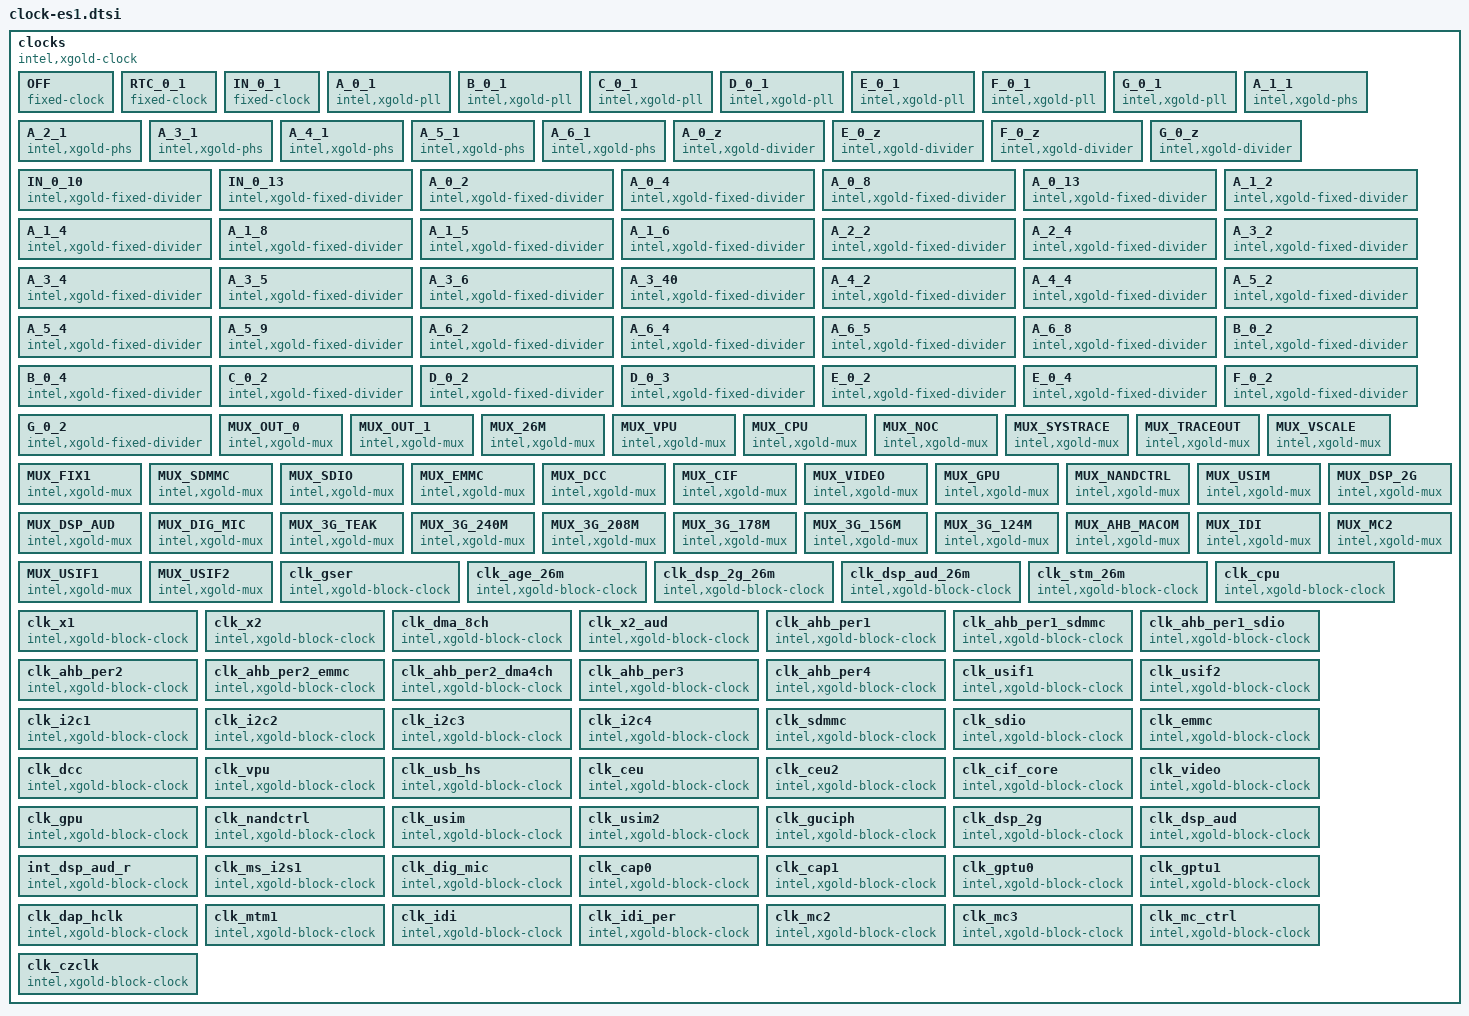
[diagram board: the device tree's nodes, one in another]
clocks {
	compatible = "intel,xgold-clock";
	intel,reg-phys = <&cgu>;
	intel,reg-defaults = <1364 0xFFFFFFFF 2636 0x0 2652 0x0 384 0x0 2640 0x0 2592 0x10008 2632 0x0 1360 0xFFFFFFFF 2644 0x30 2656 0x2495A 2660 0xE1FF0000 1368 0xFFFFFFFF>;
	intel,vreq-mapping = <1 2 3 7>;
	intel,cpu-vreq = <2652 7 3>;
	intel,global-vreq = <2652 10 3>;
	OFF:OFF {
		compatible = "fixed-clock";
		#clock-cells = <0>;
		clock-frequency= <0>;
		clock-output-names = "OFF";
	};
	RTC_0_1:RTC_0_1 {
		compatible = "fixed-clock";
		#clock-cells = <0>;
		clock-frequency= <32000>;
		clock-output-names = "RTC_0_1";
	};
	IN_0_1:IN_0_1 {
		compatible = "fixed-clock";
		#clock-cells = <0>;
		clock-frequency= <26000000>;
		clock-output-names = "IN_0_1";
	};
	A_0_1:A_0_1 {
		compatible = "intel,xgold-pll";
		#clock-cells = <0>;
		clock-frequency= <416000000>;
		clock-output-names = "A_0_1";
		clocks = <&IN_0_1>;
		clock-names = "ref";
		intel,pll-type = "analog";
		intel,pll-parameters = < 15 0 15 0 15 0 >;
		intel,mux-banks = < 3 >;
		intel,pll-mux = <292 8 1 296 8 1 300 8 1>;
		intel,pll-mult = <288 16 8>;
		intel,pll-up = <288 0 1>;
		intel,pll-div = <288 12 4>;
		intel,pll-status-lock = <356 16 1>;
		intel,pll-status-mux = <360 8 1>;
	};
	B_0_1:B_0_1 {
		compatible = "intel,xgold-pll";
		#clock-cells = <0>;
		clock-frequency= <1000000000>;
		clock-output-names = "B_0_1";
		clocks = <&IN_0_1>;
		clock-names = "ref";
		intel,flags-cpu;
		intel,pll-type = "digital";
		intel,pll-parameters = < 720896 1 983040 1 1950956 1 2455080 1 >;
		intel,pll-up-init = < 1 1 1 1 >;
		intel,frequency-banks = < 4 >;
		intel,mux-banks = < 4 >;
		intel,pll-mux = <304 1 1 996 1 1 1000 1 1 1004 1 1>;
		intel,pll-mult = <304 4 23 996 4 23 1000 4 23 1004 4 23>;
		intel,pll-up = <304 0 1 996 0 1 1000 0 1 1004 0 1>;
		intel,pll-status-lock = <356 17 1>;
		intel,pll-shpu = <304 3 1 996 3 1 1000 3 1 1004 3 1>;
		intel,pll-update = <348 17 1>;
	};
	C_0_1:C_0_1 {
		compatible = "intel,xgold-pll";
		#clock-cells = <0>;
		clock-frequency= <442000000>;
		clock-output-names = "C_0_1";
		clocks = <&IN_0_1>;
		clock-names = "ref";
		intel,pll-type = "analog";
		intel,pll-parameters = < 16 0 16 0 16 0 >;
		intel,pll-mux = <308 8 1>;
		intel,pll-mult = <308 16 8>;
		intel,pll-up = <308 0 1>;
		intel,pll-div = <308 12 4>;
		intel,pll-status-lock = <356 18 1>;
	};
	D_0_1:D_0_1 {
		compatible = "intel,xgold-pll";
		#clock-cells = <0>;
		clock-frequency= <312000000>;
		clock-output-names = "D_0_1";
		clocks = <&IN_0_1>;
		clock-names = "ref";
		intel,pll-type = "analog";
		intel,pll-parameters = < 11 0 11 0 11 0 >;
		intel,pll-up = <372 28 1>;
		intel,pll-status-lock = <356 19 1>;
	};
	E_0_1:E_0_1 {
		compatible = "intel,xgold-pll";
		#clock-cells = <0>;
		clock-frequency= <480000000>;
		clock-output-names = "E_0_1";
		clocks = <&IN_0_1>;
		clock-names = "ref";
		intel,pll-type = "digital";
		intel,pll-parameters = < 1144359 1 >;
		intel,pll-mux = <312 1 1>;
		intel,pll-mult = <312 4 23>;
		intel,pll-up = <312 0 1>;
		intel,pll-status-lock = <356 20 1>;
		intel,pll-update = <348 20 1>;
	};
	F_0_1:F_0_1 {
		compatible = "intel,xgold-pll";
		#clock-cells = <0>;
		clock-frequency= <800000000>;
		clock-output-names = "F_0_1";
		clocks = <&IN_0_1>;
		clock-names = "ref";
		intel,flags-noinit;
		intel,flags-ignore-unused;
		intel,pll-type = "digital";
		intel,pll-parameters = < 1114112 1 >;
		intel,pll-mux = <320 1 1>;
		intel,pll-mult = <320 4 23>;
		intel,pll-up = <320 0 1>;
		intel,pll-status-lock = <356 21 1>;
		intel,pll-shpu = <320 3 1>;
		intel,pll-update = <348 21 1>;
	};
	G_0_1:G_0_1 {
		compatible = "intel,xgold-pll";
		#clock-cells = <0>;
		clock-frequency= <400000000>;
		clock-output-names = "G_0_1";
		clocks = <&IN_0_1>;
		clock-names = "ref";
		intel,pll-type = "digital";
		intel,pll-parameters = < 993122 1 >;
		intel,pll-mux = <980 1 1>;
		intel,pll-mult = <980 4 23>;
		intel,pll-up = <980 0 1>;
		intel,pll-status-lock = <356 22 1>;
		intel,pll-update = <348 22 1>;
	};
	A_1_1:A_1_1 {
		compatible = "intel,xgold-phs";
		#clock-cells = <0>;
		clock-output-names = "A_1_1";
		clocks = <&A_0_1>;
		clock-names = "ref";
		intel,phs-parameters = < 2 1 >;
		intel,frequency-banks = < 3 >;
		intel,mux-banks = < 3 >;
		intel,phs-mux = <292 9 1 296 9 1 300 9 1>;
		intel,phs-Y = <324 3 4 328 3 4 332 3 4>;
		intel,phs-up = <292 1 1 296 1 1 300 1 1>;
		intel,phs-X = <324 0 3 328 0 3 332 0 3>;
		intel,phs-status-up = <360 1 1>;
		intel,phs-status-Y = <364 3 4>;
		intel,phs-status-X = <364 0 3>;
		intel,phs-status-mux = <360 9 1>;
		intel,phs-update = <348 0 1>;
	};
	A_2_1:A_2_1 {
		compatible = "intel,xgold-phs";
		#clock-cells = <0>;
		clock-output-names = "A_2_1";
		clocks = <&A_0_1>;
		clock-names = "ref";
		intel,phs-parameters = < 4 1 4 1 4 1 >;
		intel,frequency-banks = < 3 >;
		intel,mux-banks = < 3 >;
		intel,phs-mux = <292 10 1 296 10 1 300 10 1>;
		intel,phs-Y = <324 11 4 328 11 4 332 11 4>;
		intel,phs-up = <292 2 1 296 2 1 300 2 1>;
		intel,phs-X = <324 8 3 328 8 3 332 8 3>;
		intel,phs-status-up = <360 2 1>;
		intel,phs-status-Y = <364 11 4>;
		intel,phs-status-X = <364 8 3>;
		intel,phs-status-mux = <360 10 1>;
		intel,phs-update = <348 1 1>;
	};
	A_3_1:A_3_1 {
		compatible = "intel,xgold-phs";
		#clock-cells = <0>;
		clock-output-names = "A_3_1";
		clocks = <&A_0_1>;
		clock-names = "ref";
		intel,phs-parameters = < 1 2 1 2 1 2 >;
		intel,frequency-banks = < 3 >;
		intel,mux-banks = < 3 >;
		intel,phs-mux = <292 11 1 296 11 1 300 11 1>;
		intel,phs-Y = <324 19 4 328 19 4 332 19 4>;
		intel,phs-up = <292 3 1 296 3 1 300 3 1>;
		intel,phs-X = <324 16 3 328 16 3 332 16 3>;
		intel,phs-status-up = <360 3 1>;
		intel,phs-status-Y = <364 19 4>;
		intel,phs-status-X = <364 16 3>;
		intel,phs-status-mux = <360 11 1>;
		intel,phs-update = <348 2 1>;
	};
	A_4_1:A_4_1 {
		compatible = "intel,xgold-phs";
		#clock-cells = <0>;
		clock-output-names = "A_4_1";
		clocks = <&A_0_1>;
		clock-names = "ref";
		intel,phs-parameters = < 1 1 1 1 1 1 >;
		intel,frequency-banks = < 3 >;
		intel,mux-banks = < 3 >;
		intel,phs-mux = <292 12 1 296 12 1 300 12 1>;
		intel,phs-Y = <324 27 4 328 27 4 332 27 4>;
		intel,phs-up = <292 4 1 296 4 1 300 4 1>;
		intel,phs-X = <324 24 3 328 24 3 332 24 3>;
		intel,phs-status-up = <360 4 1>;
		intel,phs-status-Y = <364 27 4>;
		intel,phs-status-X = <364 24 3>;
		intel,phs-status-mux = <360 12 1>;
		intel,phs-update = <348 3 1>;
	};
	A_5_1:A_5_1 {
		compatible = "intel,xgold-phs";
		#clock-cells = <0>;
		clock-output-names = "A_5_1";
		clocks = <&A_0_1>;
		clock-names = "ref";
		intel,phs-parameters = < 3 1 3 1 3 1 >;
		intel,frequency-banks = < 3 >;
		intel,mux-banks = < 3 >;
		intel,phs-mux = <292 13 1 296 13 1 300 13 1>;
		intel,phs-Y = <336 3 4 340 3 4 344 3 4>;
		intel,phs-up = <292 5 1 296 5 1 300 5 1>;
		intel,phs-X = <336 8 3 340 8 3 344 8 3>;
		intel,phs-status-up = <360 5 1>;
		intel,phs-status-Y = <368 3 4>;
		intel,phs-status-X = <368 0 3>;
		intel,phs-status-mux = <360 13 1>;
		intel,phs-update = <348 5 1>;
	};
	A_6_1:A_6_1 {
		compatible = "intel,xgold-phs";
		#clock-cells = <0>;
		clock-output-names = "A_6_1";
		clocks = <&A_0_1>;
		clock-names = "ref";
		intel,phs-parameters = < 0 1 0 1 0 1 >;
		intel,frequency-banks = < 3 >;
		intel,mux-banks = < 3 >;
		intel,phs-mux = <292 14 1 296 14 1 300 14 1>;
		intel,phs-Y = <336 11 4 340 11 4 344 11 4>;
		intel,phs-up = <292 6 1 296 6 1 300 6 1>;
		intel,phs-X = <336 8 3 340 8 3 344 8 3>;
		intel,phs-status-up = <360 6 1>;
		intel,phs-status-Y = <368 11 4>;
		intel,phs-status-X = <368 8 3>;
		intel,phs-status-mux = <360 14 1>;
		intel,phs-update = <348 6 1>;
	};
	A_0_z:A_0_z {
		compatible = "intel,xgold-divider";
		#clock-cells = <0>;
		clock-output-names = "A_0_z";
		clocks = <&A_0_1>;
		clock-names = "ref";
		intel,divider-type = "Natural";
		intel,divider-div = <288 28 4>;
	};
	E_0_z:E_0_z {
		compatible = "intel,xgold-divider";
		#clock-cells = <0>;
		clock-output-names = "E_0_z";
		clocks = <&E_0_1>;
		clock-names = "ref";
		intel,divider-type = "Natural";
		intel,divider-div = <312 28 4>;
	};
	F_0_z:F_0_z {
		compatible = "intel,xgold-divider";
		#clock-cells = <0>;
		clock-output-names = "F_0_z";
		clocks = <&F_0_1>;
		clock-names = "ref";
		intel,divider-type = "Natural";
		intel,divider-div = <320 28 4>;
	};
	G_0_z:G_0_z {
		compatible = "intel,xgold-divider";
		#clock-cells = <0>;
		clock-output-names = "G_0_z";
		clocks = <&G_0_1>;
		clock-names = "ref";
		intel,divider-type = "Natural";
		intel,divider-div = <980 28 4>;
	};
	IN_0_10:IN_0_10 {
		compatible = "intel,xgold-fixed-divider";
		#clock-cells = <0>;
		clock-output-names = "IN_0_10";
		clocks = <&IN_0_1>;
		clock-names = "ref";
		intel,divider = < 10 >;
		intel,mult = < 1 >;
	};
	IN_0_13:IN_0_13 {
		compatible = "intel,xgold-fixed-divider";
		#clock-cells = <0>;
		clock-output-names = "IN_0_13";
		clocks = <&IN_0_1>;
		clock-names = "ref";
		intel,divider = < 13 >;
		intel,mult = < 1 >;
	};
	A_0_2:A_0_2 {
		compatible = "intel,xgold-fixed-divider";
		#clock-cells = <0>;
		clock-output-names = "A_0_2";
		clocks = <&A_0_1>;
		clock-names = "ref";
		intel,divider = < 2 >;
		intel,mult = < 1 >;
	};
	A_0_4:A_0_4 {
		compatible = "intel,xgold-fixed-divider";
		#clock-cells = <0>;
		clock-output-names = "A_0_4";
		clocks = <&A_0_1>;
		clock-names = "ref";
		intel,divider = < 4 >;
		intel,mult = < 1 >;
	};
	A_0_8:A_0_8 {
		compatible = "intel,xgold-fixed-divider";
		#clock-cells = <0>;
		clock-output-names = "A_0_8";
		clocks = <&A_0_1>;
		clock-names = "ref";
		intel,divider = < 8 >;
		intel,mult = < 1 >;
	};
	A_0_13:A_0_13 {
		compatible = "intel,xgold-fixed-divider";
		#clock-cells = <0>;
		clock-output-names = "A_0_13";
		clocks = <&A_0_1>;
		clock-names = "ref";
		intel,divider = < 13 >;
		intel,mult = < 1 >;
	};
	A_1_2:A_1_2 {
		compatible = "intel,xgold-fixed-divider";
		#clock-cells = <0>;
		clock-output-names = "A_1_2";
		clocks = <&A_1_1>;
		clock-names = "ref";
		intel,divider = < 2 >;
		intel,mult = < 1 >;
	};
	A_1_4:A_1_4 {
		compatible = "intel,xgold-fixed-divider";
		#clock-cells = <0>;
		clock-output-names = "A_1_4";
		clocks = <&A_1_1>;
		clock-names = "ref";
		intel,divider = < 4 >;
		intel,mult = < 1 >;
	};
	A_1_8:A_1_8 {
		compatible = "intel,xgold-fixed-divider";
		#clock-cells = <0>;
		clock-output-names = "A_1_8";
		clocks = <&A_1_1>;
		clock-names = "ref";
		intel,divider = < 8 >;
		intel,mult = < 1 >;
	};
	A_1_5:A_1_5 {
		compatible = "intel,xgold-fixed-divider";
		#clock-cells = <0>;
		clock-output-names = "A_1_5";
		clocks = <&A_1_1>;
		clock-names = "ref";
		intel,divider = < 5 >;
		intel,mult = < 1 >;
	};
	A_1_6:A_1_6 {
		compatible = "intel,xgold-fixed-divider";
		#clock-cells = <0>;
		clock-output-names = "A_1_6";
		clocks = <&A_1_1>;
		clock-names = "ref";
		intel,divider = < 6 >;
		intel,mult = < 1 >;
	};
	A_2_2:A_2_2 {
		compatible = "intel,xgold-fixed-divider";
		#clock-cells = <0>;
		clock-output-names = "A_2_2";
		clocks = <&A_2_1>;
		clock-names = "ref";
		intel,divider = < 2 >;
		intel,mult = < 1 >;
	};
	A_2_4:A_2_4 {
		compatible = "intel,xgold-fixed-divider";
		#clock-cells = <0>;
		clock-output-names = "A_2_4";
		clocks = <&A_2_1>;
		clock-names = "ref";
		intel,divider = < 4 >;
		intel,mult = < 1 >;
	};
	A_3_2:A_3_2 {
		compatible = "intel,xgold-fixed-divider";
		#clock-cells = <0>;
		clock-output-names = "A_3_2";
		clocks = <&A_3_1>;
		clock-names = "ref";
		intel,divider = < 2 >;
		intel,mult = < 1 >;
	};
	A_3_4:A_3_4 {
		compatible = "intel,xgold-fixed-divider";
		#clock-cells = <0>;
		clock-output-names = "A_3_4";
		clocks = <&A_3_1>;
		clock-names = "ref";
		intel,divider = < 4 >;
		intel,mult = < 1 >;
	};
	A_3_5:A_3_5 {
		compatible = "intel,xgold-fixed-divider";
		#clock-cells = <0>;
		clock-output-names = "A_3_5";
		clocks = <&A_3_1>;
		clock-names = "ref";
		intel,divider = < 5 >;
		intel,mult = < 1 >;
	};
	A_3_6:A_3_6 {
		compatible = "intel,xgold-fixed-divider";
		#clock-cells = <0>;
		clock-output-names = "A_3_6";
		clocks = <&A_3_1>;
		clock-names = "ref";
		intel,divider = < 6 >;
		intel,mult = < 1 >;
	};
	A_3_40:A_3_40 {
		compatible = "intel,xgold-fixed-divider";
		#clock-cells = <0>;
		clock-output-names = "A_3_40";
		clocks = <&A_3_1>;
		clock-names = "ref";
		intel,divider = < 40 >;
		intel,mult = < 1 >;
	};
	A_4_2:A_4_2 {
		compatible = "intel,xgold-fixed-divider";
		#clock-cells = <0>;
		clock-output-names = "A_4_2";
		clocks = <&A_4_1>;
		clock-names = "ref";
		intel,divider = < 2 >;
		intel,mult = < 1 >;
	};
	A_4_4:A_4_4 {
		compatible = "intel,xgold-fixed-divider";
		#clock-cells = <0>;
		clock-output-names = "A_4_4";
		clocks = <&A_4_1>;
		clock-names = "ref";
		intel,divider = < 4 >;
		intel,mult = < 1 >;
	};
	A_5_2:A_5_2 {
		compatible = "intel,xgold-fixed-divider";
		#clock-cells = <0>;
		clock-output-names = "A_5_2";
		clocks = <&A_5_1>;
		clock-names = "ref";
		intel,divider = < 2 >;
		intel,mult = < 1 >;
	};
	A_5_4:A_5_4 {
		compatible = "intel,xgold-fixed-divider";
		#clock-cells = <0>;
		clock-output-names = "A_5_4";
		clocks = <&A_5_1>;
		clock-names = "ref";
		intel,divider = < 4 >;
		intel,mult = < 1 >;
	};
	A_5_9:A_5_9 {
		compatible = "intel,xgold-fixed-divider";
		#clock-cells = <0>;
		clock-output-names = "A_5_9";
		clocks = <&A_5_1>;
		clock-names = "ref";
		intel,divider = < 9 >;
		intel,mult = < 1 >;
	};
	A_6_2:A_6_2 {
		compatible = "intel,xgold-fixed-divider";
		#clock-cells = <0>;
		clock-output-names = "A_6_2";
		clocks = <&A_6_1>;
		clock-names = "ref";
		intel,divider = < 2 >;
		intel,mult = < 1 >;
	};
	A_6_4:A_6_4 {
		compatible = "intel,xgold-fixed-divider";
		#clock-cells = <0>;
		clock-output-names = "A_6_4";
		clocks = <&A_6_1>;
		clock-names = "ref";
		intel,divider = < 4 >;
		intel,mult = < 1 >;
	};
	A_6_5:A_6_5 {
		compatible = "intel,xgold-fixed-divider";
		#clock-cells = <0>;
		clock-output-names = "A_6_5";
		clocks = <&A_6_1>;
		clock-names = "ref";
		intel,divider = < 5 >;
		intel,mult = < 1 >;
	};
	A_6_8:A_6_8 {
		compatible = "intel,xgold-fixed-divider";
		#clock-cells = <0>;
		clock-output-names = "A_6_8";
		clocks = <&A_6_1>;
		clock-names = "ref";
		intel,divider = < 8 >;
		intel,mult = < 1 >;
	};
	B_0_2:B_0_2 {
		compatible = "intel,xgold-fixed-divider";
		#clock-cells = <0>;
		clock-output-names = "B_0_2";
		clocks = <&B_0_1>;
		clock-names = "ref";
		intel,divider = < 2 >;
		intel,mult = < 1 >;
	};
	B_0_4:B_0_4 {
		compatible = "intel,xgold-fixed-divider";
		#clock-cells = <0>;
		clock-output-names = "B_0_4";
		clocks = <&B_0_1>;
		clock-names = "ref";
		intel,divider = < 4 >;
		intel,mult = < 1 >;
	};
	C_0_2:C_0_2 {
		compatible = "intel,xgold-fixed-divider";
		#clock-cells = <0>;
		clock-output-names = "C_0_2";
		clocks = <&C_0_1>;
		clock-names = "ref";
		intel,divider = < 2 >;
		intel,mult = < 1 >;
	};
	D_0_2:D_0_2 {
		compatible = "intel,xgold-fixed-divider";
		#clock-cells = <0>;
		clock-output-names = "D_0_2";
		clocks = <&D_0_1>;
		clock-names = "ref";
		intel,divider = < 2 >;
		intel,mult = < 1 >;
	};
	D_0_3:D_0_3 {
		compatible = "intel,xgold-fixed-divider";
		#clock-cells = <0>;
		clock-output-names = "D_0_3";
		clocks = <&D_0_1>;
		clock-names = "ref";
		intel,divider = < 3 >;
		intel,mult = < 1 >;
	};
	E_0_2:E_0_2 {
		compatible = "intel,xgold-fixed-divider";
		#clock-cells = <0>;
		clock-output-names = "E_0_2";
		clocks = <&E_0_1>;
		clock-names = "ref";
		intel,divider = < 2 >;
		intel,mult = < 1 >;
	};
	E_0_4:E_0_4 {
		compatible = "intel,xgold-fixed-divider";
		#clock-cells = <0>;
		clock-output-names = "E_0_4";
		clocks = <&E_0_1>;
		clock-names = "ref";
		intel,divider = < 4 >;
		intel,mult = < 1 >;
	};
	F_0_2:F_0_2 {
		compatible = "intel,xgold-fixed-divider";
		#clock-cells = <0>;
		clock-output-names = "F_0_2";
		clocks = <&F_0_1>;
		clock-names = "ref";
		intel,divider = < 2 >;
		intel,mult = < 1 >;
	};
	G_0_2:G_0_2 {
		compatible = "intel,xgold-fixed-divider";
		#clock-cells = <0>;
		clock-output-names = "G_0_2";
		clocks = <&G_0_1>;
		clock-names = "ref";
		intel,divider = < 2 >;
		intel,mult = < 1 >;
	};
	MUX_OUT_0:MUX_OUT_0 {
		compatible = "intel,xgold-mux";
		#clock-cells = <0>;
		clock-output-names = "mclk_out_0";
		clocks = < &OFF >, < &RTC_0_1 >, < &IN_0_1 >, < &A_0_z >, < &A_2_2 >, < &A_4_2 >, < &A_3_2 >, < &A_1_2 >, < &A_6_2 > ;
		clock-names = "ref";
		intel,frequency-banks = < 3 >;
		intel,mux-type = "power";
		intel,mux-default = < 0 0 0 >;
		intel,mux-update = <488 23 1>;
		intel,mux-sleep = <476 31 1>;
		intel,mux-status-select = <496 4 4>;
		intel,mux-select = <476 0 8 476 8 8 476 16 8>;
	};
	MUX_OUT_1:MUX_OUT_1 {
		compatible = "intel,xgold-mux";
		#clock-cells = <0>;
		clock-output-names = "mclk_out_1";
		clocks = < &OFF >, < &RTC_0_1 >, < &IN_0_1 >, < &A_0_z >, < &A_2_2 >, < &A_4_2 >, < &A_3_2 >, < &A_5_2 >, < &A_6_2 > ;
		clock-names = "ref";
		intel,frequency-banks = < 3 >;
		intel,mux-type = "power";
		intel,mux-default = < 2 2 2 >;
		intel,mux-update = <488 24 1>;
		intel,mux-sleep = <480 31 1>;
		intel,mux-status-select = <496 8 4>;
		intel,mux-select = <480 0 8 480 8 8 480 16 8>;
	};
	MUX_26M:MUX_26M {
		compatible = "intel,xgold-mux";
		#clock-cells = <0>;
		clock-output-names = "mclk_26m";
		clocks = < &OFF >, < &RTC_0_1 >, < &IN_0_1 > ;
		clock-names = "ref";
		intel,frequency-banks = < 3 >;
		intel,mux-type = "power";
		intel,mux-default = < 2 2 2 >;
		intel,mux-update = <488 0 1>;
		intel,mux-status-select = <496 28 4>;
		intel,mux-select = <392 0 8 392 8 8 392 16 8>;
	};
	MUX_VPU:MUX_VPU {
		compatible = "intel,xgold-mux";
		#clock-cells = <0>;
		clock-output-names = "mclk_vpu";
		clocks = < &OFF >, < &RTC_0_1 >, < &IN_0_1 >, < &A_5_1 >, < &A_2_1 >, < &A_0_4 >, < &A_1_8 >, < &A_3_2 >, < &A_1_2 > ;
		clock-names = "ref";
		intel,frequency-banks = < 3 >;
		intel,mux-type = "power";
		intel,mux-default = < 16 16 16 >;
		intel,mux-update = <488 2 1>;
		intel,mux-sleep = <796 31 1>;
		intel,mux-status-select = <500 28 4>;
		intel,mux-select = <796 0 8 796 8 8 796 16 8>;
	};
	MUX_CPU:MUX_CPU {
		compatible = "intel,xgold-mux";
		#clock-cells = <0>;
		clock-output-names = "mclk_cpu";
		clocks = < &OFF >, < &RTC_0_1 >, < &IN_0_1 >, < &G_0_1 >, < &G_0_2 >, < &B_0_1 >, < &A_0_2 >, < &D_0_1 >, < &A_0_1 > ;
		clock-names = "ref";
		intel,flags-cpu;
		intel,frequency-banks = < 4 >;
		intel,mux-type = "power";
		intel,mux-default = < 128 16 16 16 >;
		intel,mux-default-div-fix = < 4 >;
		intel,mux-update = <488 8 1>;
		intel,mux-sleep = <428 31 1>;
		intel,mux-status-select = <496 0 4>;
		intel,mux-select = <428 0 8 428 8 8 428 16 8 428 24 5>;
		intel,mux-divfix = <692 0 10>;
	};
	MUX_NOC:MUX_NOC {
		compatible = "intel,xgold-mux";
		#clock-cells = <0>;
		clock-output-names = "mclk_noc";
		clocks = < &OFF >, < &RTC_0_1 >, < &IN_0_1 >, < &G_0_1 >, < &E_0_1 >, < &B_0_2 >, < &A_0_4 >, < &D_0_1 >, < &D_0_2 > ;
		clock-names = "ref";
		intel,frequency-banks = < 4 >;
		intel,mux-type = "power";
		intel,mux-default = < 32 128 4 4 >;
		intel,mux-default-div-fix = < 8 >;
		intel,mux-update = <488 15 1>;
		intel,mux-sleep = <424 31 1>;
		intel,mux-status-select = <496 12 4>;
		intel,mux-select = <424 0 8 424 8 8 424 16 8 424 24 5>;
	};
	MUX_SYSTRACE:MUX_SYSTRACE {
		compatible = "intel,xgold-mux";
		#clock-cells = <0>;
		clock-output-names = "mclk_systrace";
		clocks = < &OFF >, < &RTC_0_1 >, < &IN_0_1 >, < &A_5_2 >, < &D_0_2 >, < &A_4_2 >, < &A_0_4 >, < &A_0_2 >, < &D_0_1 > ;
		clock-names = "ref";
		intel,frequency-banks = < 3 >;
		intel,mux-type = "power";
		intel,mux-default = < 8 64 128 >;
		intel,mux-update = <488 27 1>;
		intel,mux-sleep = <468 31 1>;
		intel,mux-status-select = <496 16 4>;
		intel,mux-select = <468 0 8 468 8 8 468 16 8>;
	};
	MUX_TRACEOUT:MUX_TRACEOUT {
		compatible = "intel,xgold-mux";
		#clock-cells = <0>;
		clock-output-names = "mclk_traceout";
		clocks = < &OFF >, < &RTC_0_1 >, < &IN_0_1 >, < &A_5_2 >, < &A_0_2 >, < &G_0_z >, < &D_0_1 >, < &A_0_1 >, < &C_0_1 > ;
		clock-names = "ref";
		intel,frequency-banks = < 3 >;
		intel,mux-type = "power";
		intel,mux-default = < 8 32 128 >;
		intel,mux-update = <488 28 1>;
		intel,mux-sleep = <472 31 1>;
		intel,mux-status-select = <512 0 4>;
		intel,mux-select = <472 0 8 472 8 8 472 16 8>;
	};
	MUX_VSCALE:MUX_VSCALE {
		compatible = "intel,xgold-mux";
		#clock-cells = <0>;
		clock-output-names = "mclk_vscale";
		clocks = < &OFF >, < &RTC_0_1 >, < &IN_0_1 >, < &A_1_4 >, < &A_0_4 >, < &D_0_3 >, < &A_6_4 >, < &A_6_8 >, < &A_0_8 > ;
		clock-names = "ref";
		intel,frequency-banks = < 3 >;
		intel,mux-type = "power";
		intel,mux-default = < 8 4 8 >;
		intel,mux-update = <488 20 1>;
		intel,mux-status-select = <500 0 4>;
		intel,mux-select = <484 0 8 484 8 8 484 16 8>;
		intel,mux-divfix = <684 0 10>;
	};
	MUX_FIX1:MUX_FIX1 {
		compatible = "intel,xgold-mux";
		#clock-cells = <0>;
		clock-output-names = "mclk_fix1";
		clocks = < &OFF >, < &RTC_0_1 >, < &IN_0_1 >, < &A_3_2 >, < &A_0_4 >, < &D_0_3 >, < &A_1_4 >, < &A_0_2 >, < &A_6_4 > ;
		clock-names = "ref";
		intel,frequency-banks = < 3 >;
		intel,mux-type = "custom";
		intel,mux-selectors = < 0 1 2 4 8 16 32 64 64 > ;
		intel,mux-default = < 8 8 8 >;
		intel,mux-update = <488 14 1>;
		intel,mux-sleep = <456 31 1>;
		intel,mux-status-select = <500 8 4>;
		intel,mux-select = <456 0 8 456 8 8 456 16 8>;
		intel,mux-divfix = <688 0 10>;
	};
	MUX_SDMMC:MUX_SDMMC {
		compatible = "intel,xgold-mux";
		#clock-cells = <0>;
		clock-output-names = "mclk_sdmmc";
		clocks = < &OFF >, < &RTC_0_1 >, < &IN_0_1 >, < &A_3_4 >, < &A_0_8 >, < &A_0_4 >, < &A_1_8 >, < &A_3_2 >, < &A_1_4 > ;
		clock-names = "ref";
		intel,frequency-banks = < 3 >;
		intel,mux-type = "power";
		intel,mux-default = < 4 64 64 >;
		intel,mux-update = <488 16 1>;
		intel,mux-sleep = <464 31 1>;
		intel,mux-status-select = <504 4 4>;
		intel,mux-select = <464 0 8 464 8 8 464 16 8>;
	};
	MUX_SDIO:MUX_SDIO {
		compatible = "intel,xgold-mux";
		#clock-cells = <0>;
		clock-output-names = "mclk_sdio";
		clocks = < &OFF >, < &RTC_0_1 >, < &IN_0_1 >, < &A_3_4 >, < &A_0_8 >, < &A_0_4 >, < &A_1_8 >, < &A_3_2 >, < &A_1_4 > ;
		clock-names = "ref";
		intel,frequency-banks = < 3 >;
		intel,mux-type = "power";
		intel,mux-default = < 4 64 64 >;
		intel,mux-update = <488 17 1>;
		intel,mux-sleep = <808 31 1>;
		intel,mux-status-select = <504 8 4>;
		intel,mux-select = <808 0 8 808 8 8 808 16 8>;
	};
	MUX_EMMC:MUX_EMMC {
		compatible = "intel,xgold-mux";
		#clock-cells = <0>;
		clock-output-names = "mclk_emmc";
		clocks = < &OFF >, < &RTC_0_1 >, < &IN_0_1 >, < &A_3_4 >, < &A_0_8 >, < &A_0_4 >, < &A_1_8 >, < &A_3_2 >, < &A_1_4 > ;
		clock-names = "ref";
		intel,frequency-banks = < 3 >;
		intel,mux-type = "power";
		intel,mux-default = < 16 128 16 >;
		intel,mux-update = <488 18 1>;
		intel,mux-sleep = <812 31 1>;
		intel,mux-status-select = <504 12 4>;
		intel,mux-select = <812 0 8 812 8 8 812 16 8>;
	};
	MUX_DCC:MUX_DCC {
		compatible = "intel,xgold-mux";
		#clock-cells = <0>;
		clock-output-names = "mclk_dcc";
		clocks = < &OFF >, < &RTC_0_1 >, < &IN_0_1 >, < &C_0_1 >, < &A_0_1 >, < &B_0_2 >, < &E_0_1 >, < &D_0_2 >, < &A_0_8 > ;
		clock-names = "ref";
		intel,frequency-banks = < 4 >;
		intel,mux-type = "power";
		intel,mux-default = < 128 64 4 16 >;
		intel,mux-update = <488 11 1>;
		intel,mux-sleep = <816 31 1>;
		intel,mux-status-select = <500 20 4>;
		intel,mux-select = <816 0 8 816 8 8 816 16 8 816 24 7>;
		intel,mux-divfix = <688 11 10>;
	};
	MUX_CIF:MUX_CIF {
		compatible = "intel,xgold-mux";
		#clock-cells = <0>;
		clock-output-names = "mclk_cif";
		clocks = < &OFF >, < &RTC_0_1 >, < &IN_0_1 >, < &A_0_4 >, < &D_0_1 >, < &A_0_2 >, < &A_0_1 >, < &A_1_2 >, < &C_0_1 > ;
		clock-names = "ref";
		intel,frequency-banks = < 3 >;
		intel,mux-type = "power";
		intel,mux-default = < 4 64 128 >;
		intel,mux-update = <488 10 1>;
		intel,mux-sleep = <820 31 1>;
		intel,mux-status-select = <500 24 4>;
		intel,mux-select = <820 0 8 820 8 8 820 16 8>;
		intel,mux-divfix = <688 22 10>;
	};
	MUX_VIDEO:MUX_VIDEO {
		compatible = "intel,xgold-mux";
		#clock-cells = <0>;
		clock-output-names = "mclk_video";
		clocks = < &OFF >, < &RTC_0_1 >, < &IN_0_1 >, < &A_0_4 >, < &D_0_1 >, < &A_0_1 >, < &G_0_1 >, < &E_0_2 >, < &A_1_2 > ;
		clock-names = "ref";
		intel,frequency-banks = < 4 >;
		intel,mux-type = "power";
		intel,mux-default = < 4 128 16 16 >;
		intel,mux-update = <488 26 1>;
		intel,mux-sleep = <824 31 1>;
		intel,mux-status-select = <504 28 4>;
		intel,mux-select = <824 0 8 824 8 8 824 16 8 824 24 7>;
	};
	MUX_GPU:MUX_GPU {
		compatible = "intel,xgold-mux";
		#clock-cells = <0>;
		clock-output-names = "mclk_gpu";
		clocks = < &OFF >, < &RTC_0_1 >, < &IN_0_1 >, < &E_0_1 >, < &D_0_1 >, < &A_0_1 >, < &C_0_1 >, < &B_0_2 >, < &A_0_2 > ;
		clock-names = "ref";
		intel,frequency-banks = < 4 >;
		intel,mux-type = "power";
		intel,mux-default = < 8 8 32 64 >;
		intel,mux-update = <488 22 1>;
		intel,mux-sleep = <860 31 1>;
		intel,mux-status-select = <504 0 4>;
		intel,mux-select = <860 0 8 860 8 8 860 16 8 860 24 7>;
	};
	MUX_NANDCTRL:MUX_NANDCTRL {
		compatible = "intel,xgold-mux";
		#clock-cells = <0>;
		clock-output-names = "mclk_nandctrl";
		clocks = < &OFF >, < &RTC_0_1 >, < &IN_0_1 >, < &A_0_2 >, < &A_4_2 >, < &A_1_2 >, < &A_2_2 >, < &A_0_4 > ;
		clock-names = "ref";
		intel,frequency-banks = < 3 >;
		intel,mux-type = "power";
		intel,mux-default = < 64 16 4 >;
		intel,mux-update = <488 4 1>;
		intel,mux-sleep = <848 31 1>;
		intel,mux-status-select = <504 24 4>;
		intel,mux-select = <848 0 8 848 8 8 848 16 8>;
	};
	MUX_USIM:MUX_USIM {
		compatible = "intel,xgold-mux";
		#clock-cells = <0>;
		clock-output-names = "mclk_usim";
		clocks = < &OFF >, < &RTC_0_1 >, < &IN_0_1 >, < &A_1_4 > ;
		clock-names = "ref";
		intel,frequency-banks = < 3 >;
		intel,mux-type = "power";
		intel,mux-default = < 0 0 0 >;
		intel,mux-update = <488 5 1>;
		intel,mux-sleep = <852 31 1>;
		intel,mux-status-select = <504 20 4>;
		intel,mux-select = <852 0 8 852 8 8 852 16 8>;
	};
	MUX_DSP_2G:MUX_DSP_2G {
		compatible = "intel,xgold-mux";
		#clock-cells = <0>;
		clock-output-names = "mclk_dsp_2g";
		clocks = < &OFF >, < &RTC_0_1 >, < &IN_0_1 >, < &A_5_1 >, < &A_0_4 >, < &A_4_2 >, < &A_5_2 >, < &A_1_2 >, < &A_0_2 > ;
		clock-names = "ref";
		intel,frequency-banks = < 3 >;
		intel,mux-type = "power";
		intel,mux-default = < 0 0 0 >;
		intel,mux-update = <488 1 1>;
		intel,mux-sleep = <432 31 1>;
		intel,mux-status-select = <496 24 4>;
		intel,mux-select = <432 0 8 432 8 8 432 16 8>;
	};
	MUX_DSP_AUD:MUX_DSP_AUD {
		compatible = "intel,xgold-mux";
		#clock-cells = <0>;
		clock-output-names = "mclk_dsp_aud";
		clocks = < &OFF >, < &RTC_0_1 >, < &IN_0_1 >, < &A_5_1 >, < &A_0_4 >, < &A_4_2 >, < &A_5_2 >, < &A_1_2 >, < &A_0_2 > ;
		clock-names = "ref";
		intel,frequency-banks = < 3 >;
		intel,mux-type = "power";
		intel,mux-default = < 8 32 4 >;
		intel,mux-update = <488 3 1>;
		intel,mux-sleep = <444 31 1>;
		intel,mux-status-select = <504 16 4>;
		intel,mux-select = <444 0 8 444 8 8 444 16 8>;
	};
	MUX_DIG_MIC:MUX_DIG_MIC {
		compatible = "intel,xgold-mux";
		#clock-cells = <0>;
		clock-output-names = "mclk_dig_mic";
		clocks = < &OFF >, < &RTC_0_1 >, < &IN_0_1 >, < &A_3_2 >, < &A_0_8 >, < &A_1_4 >, < &D_0_3 >, < &E_0_4 >, < &A_6_4 > ;
		clock-names = "ref";
		intel,frequency-banks = < 3 >;
		intel,mux-type = "power";
		intel,mux-default = < 4 4 4 >;
		intel,mux-update = <488 6 1>;
		intel,mux-sleep = <784 31 1>;
		intel,mux-select = <784 0 8 784 8 8 784 16 8>;
	};
	MUX_3G_TEAK:MUX_3G_TEAK {
		compatible = "intel,xgold-mux";
		#clock-cells = <0>;
		clock-output-names = "mclk_3g_teak";
		clocks = < &OFF >, < &RTC_0_1 >, < &IN_0_1 >, < &A_5_2 >, < &A_0_2 >, < &A_6_2 >, < &A_6_4 > ;
		clock-names = "ref";
		intel,frequency-banks = < 3 >;
		intel,mux-type = "power";
		intel,mux-default = < 0 0 0 >;
		intel,mux-update = <492 1 1>;
		intel,mux-sleep = <412 31 1>;
		intel,mux-status-select = <508 12 4>;
		intel,mux-select = <412 0 8 412 8 8 412 16 8>;
	};
	MUX_3G_240M:MUX_3G_240M {
		compatible = "intel,xgold-mux";
		#clock-cells = <0>;
		clock-output-names = "mclk_3g_240m";
		clocks = < &OFF >, < &RTC_0_1 >, < &IN_0_1 >, < &A_2_2 >, < &A_0_2 >, < &E_0_2 >, < &C_0_2 >, < &E_0_z >, < &A_6_2 > ;
		clock-names = "ref";
		intel,frequency-banks = < 3 >;
		intel,mux-type = "power";
		intel,mux-default = < 0 0 0 >;
		intel,mux-update = <492 5 1>;
		intel,mux-sleep = <396 31 1>;
		intel,mux-status-select = <508 28 4>;
		intel,mux-select = <396 0 8 396 8 8 396 16 8>;
	};
	MUX_3G_208M:MUX_3G_208M {
		compatible = "intel,xgold-mux";
		#clock-cells = <0>;
		clock-output-names = "mclk_3g_208m";
		clocks = < &OFF >, < &RTC_0_1 >, < &IN_0_1 >, < &A_0_2 >, < &A_6_2 >, < &A_6_4 > ;
		clock-names = "ref";
		intel,frequency-banks = < 3 >;
		intel,mux-type = "power";
		intel,mux-default = < 0 0 0 >;
		intel,mux-update = <492 4 1>;
		intel,mux-sleep = <400 31 1>;
		intel,mux-status-select = <508 24 4>;
		intel,mux-select = <400 0 8 400 8 8 400 16 8>;
	};
	MUX_3G_178M:MUX_3G_178M {
		compatible = "intel,xgold-mux";
		#clock-cells = <0>;
		clock-output-names = "mclk_3g_178m";
		clocks = < &OFF >, < &RTC_0_1 >, < &IN_0_1 >, < &A_4_2 >, < &A_6_2 >, < &A_6_4 > ;
		clock-names = "ref";
		intel,frequency-banks = < 3 >;
		intel,mux-type = "power";
		intel,mux-default = < 0 0 0 >;
		intel,mux-update = <492 3 1>;
		intel,mux-sleep = <404 31 1>;
		intel,mux-status-select = <508 20 4>;
		intel,mux-select = <404 0 8 404 8 8 404 16 8>;
	};
	MUX_3G_156M:MUX_3G_156M {
		compatible = "intel,xgold-mux";
		#clock-cells = <0>;
		clock-output-names = "mclk_3g_156m";
		clocks = < &OFF >, < &RTC_0_1 >, < &IN_0_1 >, < &A_1_2 >, < &A_6_2 >, < &A_6_4 > ;
		clock-names = "ref";
		intel,frequency-banks = < 3 >;
		intel,mux-type = "power";
		intel,mux-default = < 0 0 0 >;
		intel,mux-update = <492 2 1>;
		intel,mux-sleep = <408 31 1>;
		intel,mux-status-select = <508 16 4>;
		intel,mux-select = <408 0 8 408 8 8 408 16 8>;
	};
	MUX_3G_124M:MUX_3G_124M {
		compatible = "intel,xgold-mux";
		#clock-cells = <0>;
		clock-output-names = "mclk_3g_124m";
		clocks = < &OFF >, < &RTC_0_1 >, < &IN_0_1 >, < &A_2_2 >, < &A_6_2 >, < &A_6_4 > ;
		clock-names = "ref";
		intel,frequency-banks = < 3 >;
		intel,mux-type = "power";
		intel,mux-default = < 0 0 0 >;
		intel,mux-update = <492 0 1>;
		intel,mux-sleep = <416 31 1>;
		intel,mux-status-select = <508 8 4>;
		intel,mux-select = <416 0 8 416 8 8 416 16 8>;
	};
	MUX_AHB_MACOM:MUX_AHB_MACOM {
		compatible = "intel,xgold-mux";
		#clock-cells = <0>;
		clock-output-names = "mclk_ahb_macom";
		clocks = < &OFF >, < &RTC_0_1 >, < &IN_0_1 >, < &A_0_4 >, < &A_2_2 >, < &A_4_4 >, < &A_2_4 >, < &A_0_8 >, < &A_1_4 > ;
		clock-names = "ref";
		intel,frequency-banks = < 3 >;
		intel,mux-type = "power";
		intel,mux-default = < 2 2 2 >;
		intel,mux-update = <492 6 1>;
		intel,mux-sleep = <420 31 1>;
		intel,mux-status-select = <508 4 4>;
		intel,mux-select = <420 0 8 420 8 8 420 16 8>;
	};
	MUX_IDI:MUX_IDI {
		compatible = "intel,xgold-mux";
		#clock-cells = <0>;
		clock-output-names = "mclk_idi";
		clocks = < &OFF >, < &RTC_0_1 >, < &IN_0_1 >, < &A_4_2 >, < &A_0_2 >, < &A_1_2 >, < &A_5_2 >, < &A_2_2 >, < &A_0_4 > ;
		clock-names = "ref";
		intel,frequency-banks = < 3 >;
		intel,mux-type = "power";
		intel,mux-default = < 128 16 8 >;
		intel,mux-update = <488 29 1>;
		intel,mux-sleep = <804 31 1>;
		intel,mux-status-select = <508 0 4>;
		intel,mux-select = <804 0 8 804 8 8 804 16 8>;
		intel,mux-divfix = <692 22 10>;
	};
	MUX_MC2:MUX_MC2 {
		compatible = "intel,xgold-mux";
		#clock-cells = <0>;
		clock-output-names = "mclk_mc2";
		clocks = < &OFF >, < &RTC_0_1 >, < &IN_0_1 >, < &A_4_2 >, < &A_0_2 >, < &A_1_2 >, < &B_0_4 >, < &D_0_2 >, < &E_0_2 > ;
		clock-names = "ref";
		intel,flags-noinit;
		intel,frequency-banks = < 3 >;
		intel,mux-type = "power";
		intel,mux-default = < 0 0 0 >;
		intel,mux-update = <488 13 1>;
		intel,mux-sleep = <840 31 1>;
		intel,mux-status-select = <500 12 4>;
		intel,mux-select = <840 0 8 840 8 8 840 16 8>;
	};
	MUX_USIF1:MUX_USIF1 {
		compatible = "intel,xgold-mux";
		#clock-cells = <0>;
		clock-output-names = "mclk_usif1";
		clocks = < &OFF >, < &RTC_0_1 >, < &IN_0_1 >, < &A_3_4 >, < &A_0_8 >, < &A_0_4 >, < &A_1_8 >, < &A_3_2 >, < &A_1_4 > ;
		clock-names = "ref";
		intel,frequency-banks = < 3 >;
		intel,mux-type = "power";
		intel,mux-default = < 16 16 16 >;
		intel,mux-update = <488 7 1>;
		intel,mux-sleep = <788 31 1>;
		intel,mux-status-select = <512 12 4>;
		intel,mux-select = <788 0 8 788 8 8 788 16 8>;
		intel,mux-divfix = <684 11 10>;
	};
	MUX_USIF2:MUX_USIF2 {
		compatible = "intel,xgold-mux";
		#clock-cells = <0>;
		clock-output-names = "mclk_usif2";
		clocks = < &OFF >, < &RTC_0_1 >, < &IN_0_1 >, < &A_3_4 >, < &A_0_8 >, < &A_0_4 >, < &A_1_8 >, < &A_3_2 >, < &A_1_4 > ;
		clock-names = "ref";
		intel,frequency-banks = < 3 >;
		intel,mux-type = "power";
		intel,mux-default = < 16 16 16 >;
		intel,mux-update = <488 21 1>;
		intel,mux-sleep = <792 31 1>;
		intel,mux-status-select = <512 16 4>;
		intel,mux-select = <792 0 8 792 8 8 792 16 8>;
		intel,mux-divfix = <684 22 10>;
	};
	clk_gser:clk_gser {
		compatible = "intel,xgold-block-clock";
		#clock-cells = <0>;
		clock-output-names = "clk_gser";
		clocks = <&MUX_26M>;
		clock-names = "mux";
		intel,block-status-enable = <544 15 1>;
		intel,block-enable = <520 15 1>;
		intel,block-disable = <532 15 1>;
	};
	clk_age_26m:clk_age_26m {
		compatible = "intel,xgold-block-clock";
		#clock-cells = <0>;
		clock-output-names = "clk_age_26m";
		clocks = <&MUX_26M>;
		clock-names = "mux";
		intel,block-status-enable = <544 31 1>;
		intel,block-enable = <520 31 1>;
		intel,block-disable = <532 31 1>;
	};
	clk_dsp_2g_26m:clk_dsp_2g_26m {
		compatible = "intel,xgold-block-clock";
		#clock-cells = <0>;
		clock-output-names = "clk_dsp_2g_26m";
		clocks = <&MUX_26M>;
		clock-names = "mux";
		intel,block-status-enable = <548 2 1>;
		intel,block-enable = <524 2 1>;
		intel,block-disable = <536 2 1>;
	};
	clk_dsp_aud_26m:clk_dsp_aud_26m {
		compatible = "intel,xgold-block-clock";
		#clock-cells = <0>;
		clock-output-names = "clk_dsp_aud_26m";
		clocks = <&MUX_26M>;
		clock-names = "mux";
		intel,block-status-enable = <548 0 1>;
		intel,block-enable = <524 0 1>;
		intel,block-disable = <536 0 1>;
	};
	clk_stm_26m:clk_stm_26m {
		compatible = "intel,xgold-block-clock";
		#clock-cells = <0>;
		clock-output-names = "clk_stm_26m";
		clocks = <&MUX_26M>;
		clock-names = "mux";
		intel,block-status-enable = <548 0 1>;
		intel,block-enable = <524 0 1>;
		intel,block-disable = <536 0 1>;
	};
	clk_cpu:clk_cpu {
		compatible = "intel,xgold-block-clock";
		#clock-cells = <0>;
		clock-output-names = "clk_cpu";
		clocks = <&MUX_CPU>;
		clock-names = "mux";
		intel,flags-divider_div_fix;
		intel,frequency-banks = < 4 >;
		intel,block-divider-default = < 1 1 1 1 >;
		intel,block-divider-default-div-fix = < 4 >;
		intel,block-status-enable = <544 12 1>;
		intel,block-enable = <520 12 1>;
		intel,block-divider-status = <676 0 3>;
		intel,block-disable = <532 12 1>;
		intel,block-divider = <608 0 3 608 8 3 608 16 3 608 24 3>;
		intel,block-divider-activate = <652 12 1>;
	};
	clk_x1:clk_x1 {
		compatible = "intel,xgold-block-clock";
		#clock-cells = <0>;
		clock-output-names = "clk_x1";
		clocks = <&MUX_NOC>;
		clock-names = "mux";
		intel,flags-divider_div_fix;
		intel,frequency-banks = < 4 >;
		intel,block-divider-default = < 1 1 1 1 >;
		intel,block-divider-default-div-fix = < 8 >;
		intel,block-divider-status = <676 3 3>;
		intel,block-divider = <616 0 3 616 8 3 616 16 3 616 24 3>;
		intel,block-divider-activate = <652 13 1>;
	};
	clk_x2:clk_x2 {
		compatible = "intel,xgold-block-clock";
		#clock-cells = <0>;
		clock-output-names = "clk_x2";
		clocks = <&MUX_NOC>;
		clock-names = "mux";
		intel,flags-divider_div_fix;
		intel,frequency-banks = < 4 >;
		intel,block-divider-default = < 2 2 2 2 >;
		intel,block-divider-default-div-fix = < 8 >;
		intel,block-divider-status = <676 9 3>;
		intel,block-divider = <620 0 3 620 8 3 620 16 3 620 24 3>;
		intel,block-divider-activate = <652 14 1>;
	};
	clk_dma_8ch:clk_dma_8ch {
		compatible = "intel,xgold-block-clock";
		#clock-cells = <0>;
		clock-output-names = "clk_dma_8ch";
		clocks = <&MUX_NOC>;
		clock-names = "mux";
		intel,block-status-enable = <544 6 1>;
		intel,block-enable = <520 6 1>;
		intel,block-disable = <532 6 1>;
	};
	clk_x2_aud:clk_x2_aud {
		compatible = "intel,xgold-block-clock";
		#clock-cells = <0>;
		clock-output-names = "clk_x2_aud";
		clocks = <&MUX_NOC>;
		clock-names = "mux";
		intel,block-status-enable = <540 14 1>;
		intel,block-enable = <516 14 1>;
		intel,block-disable = <528 14 1>;
	};
	clk_ahb_per1:clk_ahb_per1 {
		compatible = "intel,xgold-block-clock";
		#clock-cells = <0>;
		clock-output-names = "clk_ahb_per1";
		clocks = <&MUX_VSCALE>;
		clock-names = "mux";
		intel,flags-divider_div_fix;
		intel,frequency-banks = < 3 >;
		intel,block-divider-default = < 2 2 2 >;
		intel,block-status-enable = <540 0 1>;
		intel,block-enable = <516 0 1>;
		intel,block-divider-status = <664 0 3>;
		intel,block-disable = <528 0 1>;
		intel,block-divider = <552 0 3 552 8 3 552 16 3>;
		intel,block-divider-activate = <652 0 1>;
	};
	clk_ahb_per1_sdmmc:clk_ahb_per1_sdmmc {
		compatible = "intel,xgold-block-clock";
		#clock-cells = <0>;
		clock-output-names = "clk_ahb_per1_sdmmc";
		clocks = <&MUX_VSCALE>;
		clock-names = "mux";
		intel,block-status-enable = <540 11 1>;
		intel,block-enable = <516 11 1>;
		intel,block-disable = <528 11 1>;
	};
	clk_ahb_per1_sdio:clk_ahb_per1_sdio {
		compatible = "intel,xgold-block-clock";
		#clock-cells = <0>;
		clock-output-names = "clk_ahb_per1_sdio";
		clocks = <&MUX_VSCALE>;
		clock-names = "mux";
		intel,block-status-enable = <540 12 1>;
		intel,block-enable = <516 12 1>;
		intel,block-disable = <528 12 1>;
	};
	clk_ahb_per2:clk_ahb_per2 {
		compatible = "intel,xgold-block-clock";
		#clock-cells = <0>;
		clock-output-names = "clk_ahb_per2";
		clocks = <&MUX_VSCALE>;
		clock-names = "mux";
		intel,flags-divider_div_fix;
		intel,frequency-banks = < 3 >;
		intel,block-divider-default = < 1 1 1 >;
		intel,block-status-enable = <540 16 1>;
		intel,block-enable = <516 16 1>;
		intel,block-divider-status = <664 3 3>;
		intel,block-disable = <528 16 1>;
		intel,block-divider = <556 0 3 556 8 3 556 16 3>;
		intel,block-divider-activate = <652 16 1>;
	};
	clk_ahb_per2_emmc:clk_ahb_per2_emmc {
		compatible = "intel,xgold-block-clock";
		#clock-cells = <0>;
		clock-output-names = "clk_ahb_per2_emmc";
		clocks = <&MUX_VSCALE>;
		clock-names = "mux";
		intel,block-status-enable = <540 13 1>;
		intel,block-enable = <516 13 1>;
		intel,block-disable = <528 13 1>;
	};
	clk_ahb_per2_dma4ch:clk_ahb_per2_dma4ch {
		compatible = "intel,xgold-block-clock";
		#clock-cells = <0>;
		clock-output-names = "clk_ahb_per2_dma4ch";
		clocks = <&MUX_VSCALE>;
		clock-names = "mux";
		intel,block-status-enable = <540 27 1>;
		intel,block-enable = <516 27 1>;
		intel,block-disable = <528 27 1>;
	};
	clk_ahb_per3:clk_ahb_per3 {
		compatible = "intel,xgold-block-clock";
		#clock-cells = <0>;
		clock-output-names = "clk_ahb_per3";
		clocks = <&MUX_VSCALE>;
		clock-names = "mux";
		intel,flags-ignore-unused;
		intel,flags-divider_div_fix;
		intel,frequency-banks = < 3 >;
		intel,block-divider-default = < 4 4 4 >;
		intel,block-status-enable = <544 1 1>;
		intel,block-enable = <520 1 1>;
		intel,block-divider-status = <664 6 3>;
		intel,block-disable = <532 1 1>;
		intel,block-divider = <560 0 3 560 8 3 560 16 3>;
		intel,block-divider-activate = <656 1 1>;
	};
	clk_ahb_per4:clk_ahb_per4 {
		compatible = "intel,xgold-block-clock";
		#clock-cells = <0>;
		clock-output-names = "clk_ahb_per4";
		clocks = <&MUX_VSCALE>;
		clock-names = "mux";
		intel,flags-divider_div_fix;
		intel,frequency-banks = < 3 >;
		intel,block-divider-default = < 4 4 4 >;
		intel,block-divider-status = <664 9 3>;
		intel,block-divider = <564 0 3 564 8 3 564 16 3>;
		intel,block-divider-activate = <652 15 1>;
	};
	clk_usif1:clk_usif1 {
		compatible = "intel,xgold-block-clock";
		#clock-cells = <0>;
		clock-output-names = "clk_usif1";
		clocks = <&MUX_USIF1>;
		clock-names = "mux";
		intel,flags-divider_div_fix;
		intel,frequency-banks = < 3 >;
		intel,block-divider-default = < 1 1 1 >;
		intel,block-status-enable = <540 1 1>;
		intel,block-enable = <516 1 1>;
		intel,block-divider-status = <664 19 3>;
		intel,block-disable = <528 1 1>;
		intel,block-divider = <576 0 3 576 8 3 576 16 3>;
		intel,block-divider-activate = <652 1 1>;
	};
	clk_usif2:clk_usif2 {
		compatible = "intel,xgold-block-clock";
		#clock-cells = <0>;
		clock-output-names = "clk_usif2";
		clocks = <&MUX_USIF2>;
		clock-names = "mux";
		intel,flags-divider_div_fix;
		intel,frequency-banks = < 3 >;
		intel,block-divider-default = < 1 1 1 >;
		intel,block-status-enable = <540 2 1>;
		intel,block-enable = <516 2 1>;
		intel,block-divider-status = <664 22 3>;
		intel,block-disable = <528 2 1>;
		intel,block-divider = <580 0 3 580 8 3 580 16 3>;
		intel,block-divider-activate = <652 2 1>;
	};
	clk_i2c1:clk_i2c1 {
		compatible = "intel,xgold-block-clock";
		#clock-cells = <0>;
		clock-output-names = "clk_i2c1";
		clocks = <&MUX_FIX1>;
		clock-names = "mux";
		intel,flags-divider_div_fix;
		intel,frequency-banks = < 3 >;
		intel,block-divider-default = < 2 2 2 >;
		intel,block-status-enable = <540 10 1>;
		intel,block-enable = <516 10 1>;
		intel,block-divider-status = <672 16 3>;
		intel,block-disable = <528 10 1>;
		intel,block-divider = <604 0 3 604 8 3 604 16 3>;
		intel,block-divider-activate = <652 10 1>;
	};
	clk_i2c2:clk_i2c2 {
		compatible = "intel,xgold-block-clock";
		#clock-cells = <0>;
		clock-output-names = "clk_i2c2";
		clocks = <&MUX_FIX1>;
		clock-names = "mux";
		intel,flags-divider_div_fix;
		intel,frequency-banks = < 3 >;
		intel,block-divider-default = < 2 2 2 >;
		intel,block-status-enable = <540 20 1>;
		intel,block-enable = <516 20 1>;
		intel,block-divider-status = <672 12 3>;
		intel,block-disable = <528 20 1>;
		intel,block-divider = <924 0 3 924 8 3 924 16 3>;
		intel,block-divider-activate = <652 20 1>;
	};
	clk_i2c3:clk_i2c3 {
		compatible = "intel,xgold-block-clock";
		#clock-cells = <0>;
		clock-output-names = "clk_i2c3";
		clocks = <&MUX_FIX1>;
		clock-names = "mux";
		intel,flags-divider_div_fix;
		intel,frequency-banks = < 3 >;
		intel,block-divider-default = < 2 2 2 >;
		intel,block-status-enable = <540 18 1>;
		intel,block-enable = <516 18 1>;
		intel,block-divider-status = <672 9 3>;
		intel,block-disable = <528 18 1>;
		intel,block-divider = <928 0 3 928 8 3 928 16 3>;
		intel,block-divider-activate = <652 18 1>;
	};
	clk_i2c4:clk_i2c4 {
		compatible = "intel,xgold-block-clock";
		#clock-cells = <0>;
		clock-output-names = "clk_i2c4";
		clocks = <&MUX_FIX1>;
		clock-names = "mux";
		intel,flags-divider_div_fix;
		intel,frequency-banks = < 3 >;
		intel,block-divider-default = < 2 2 2 >;
		intel,block-status-enable = <540 15 1>;
		intel,block-enable = <516 15 1>;
		intel,block-divider-status = <672 6 3>;
		intel,block-disable = <528 15 1>;
		intel,block-divider = <936 0 3 936 8 3 936 16 3>;
		intel,block-divider-activate = <656 30 1>;
	};
	clk_sdmmc:clk_sdmmc {
		compatible = "intel,xgold-block-clock";
		#clock-cells = <0>;
		clock-output-names = "clk_sdmmc";
		clocks = <&MUX_SDMMC>;
		clock-names = "mux";
		intel,block-status-enable = <540 3 1>;
		intel,block-enable = <516 3 1>;
		intel,block-disable = <528 3 1>;
	};
	clk_sdio:clk_sdio {
		compatible = "intel,xgold-block-clock";
		#clock-cells = <0>;
		clock-output-names = "clk_sdio";
		clocks = <&MUX_SDIO>;
		clock-names = "mux";
		intel,block-status-enable = <540 4 1>;
		intel,block-enable = <516 4 1>;
		intel,block-disable = <528 4 1>;
	};
	clk_emmc:clk_emmc {
		compatible = "intel,xgold-block-clock";
		#clock-cells = <0>;
		clock-output-names = "clk_emmc";
		clocks = <&MUX_EMMC>;
		clock-names = "mux";
		intel,block-status-enable = <540 5 1>;
		intel,block-enable = <516 5 1>;
		intel,block-disable = <528 5 1>;
	};
	clk_dcc:clk_dcc {
		compatible = "intel,xgold-block-clock";
		#clock-cells = <0>;
		clock-output-names = "clk_dcc";
		clocks = <&MUX_DCC>;
		clock-names = "mux";
		intel,flags-divider_div_fix;
		intel,frequency-banks = < 4 >;
		intel,block-divider-default = < 1 1 1 1 >;
		intel,block-status-enable = <540 7 1>;
		intel,block-enable = <516 7 1>;
		intel,block-divider-status = <668 12 3>;
		intel,block-disable = <528 7 1>;
		intel,block-divider = <932 0 3 932 8 3 932 16 3 932 24 3>;
		intel,block-divider-activate = <652 7 1>;
	};
	clk_vpu:clk_vpu {
		compatible = "intel,xgold-block-clock";
		#clock-cells = <0>;
		clock-output-names = "clk_dcc";
		clocks = <&MUX_VPU>;
		clock-names = "mux";
		intel,flags-divider_div_fix;
		intel,frequency-banks = < 3 >;
		intel,block-divider-default = < 1 1 1 >;
		intel,block-status-enable = <540 8 1>;
		intel,block-enable = <516 8 1>;
		intel,block-divider-status = <664 28 3>;
		intel,block-disable = <528 8 1>;
		intel,block-divider = <640 0 3 640 8 3 640 16 3>;
		intel,block-divider-activate = <652 6 1>;
	};
	clk_usb_hs:clk_usb_hs {
		compatible = "intel,xgold-block-clock";
		#clock-cells = <0>;
		clock-output-names = "clk_usb_hs";
		clocks = <&MUX_FIX1>;
		clock-names = "mux";
		intel,flags-divider_div_fix;
		intel,frequency-banks = < 3 >;
		intel,block-divider-default = < 4 4 4 >;
		intel,block-status-enable = <540 24 1>;
		intel,block-enable = <516 24 1>;
		intel,block-divider-status = <668 3 3>;
		intel,block-disable = <528 24 1>;
		intel,block-divider = <592 0 3 592 8 3 592 16 3>;
		intel,block-divider-activate = <652 24 1>;
	};
	clk_ceu:clk_ceu {
		compatible = "intel,xgold-block-clock";
		#clock-cells = <0>;
		clock-output-names = "clk_ceu";
		clocks = <&MUX_VSCALE>;
		clock-names = "mux";
		intel,flags-divider_div_fix;
		intel,frequency-banks = < 3 >;
		intel,block-divider-default = < 1 1 1 >;
		intel,block-status-enable = <544 29 1>;
		intel,block-enable = <520 29 1>;
		intel,block-divider-status = <676 12 3>;
		intel,block-disable = <532 29 1>;
		intel,block-divider = <624 0 3 624 8 3 624 16 3>;
		intel,block-divider-activate = <656 29 1>;
	};
	clk_ceu2:clk_ceu2 {
		compatible = "intel,xgold-block-clock";
		#clock-cells = <0>;
		clock-output-names = "clk_ceu2";
		clocks = <&MUX_VSCALE>;
		clock-names = "mux";
		intel,flags-divider_div_fix;
		intel,frequency-banks = < 3 >;
		intel,block-divider-default = < 1 1 1 >;
		intel,block-status-enable = <544 30 1>;
		intel,block-enable = <520 30 1>;
		intel,block-divider-status = <676 22 3>;
		intel,block-disable = <532 30 1>;
		intel,block-divider = <936 0 3 936 8 3 936 16 3>;
		intel,block-divider-activate = <656 30 1>;
	};
	clk_cif_core:clk_cif_core {
		compatible = "intel,xgold-block-clock";
		#clock-cells = <0>;
		clock-output-names = "clk_cif_core";
		clocks = <&MUX_CIF>;
		clock-names = "mux";
		intel,flags-divider_div_fix;
		intel,frequency-banks = < 3 >;
		intel,block-divider-default = < 1 1 1 >;
		intel,block-status-enable = <540 29 1>;
		intel,block-enable = <516 29 1>;
		intel,block-divider-status = <668 9 3>;
		intel,block-disable = <528 29 1>;
		intel,block-divider = <944 0 3 944 8 3 944 16 3>;
		intel,block-divider-activate = <652 29 1>;
	};
	clk_video:clk_video {
		compatible = "intel,xgold-block-clock";
		#clock-cells = <0>;
		clock-output-names = "clk_video";
		clocks = <&MUX_VIDEO>;
		clock-names = "mux";
		intel,flags-divider_div_fix;
		intel,frequency-banks = < 4 >;
		intel,block-divider-default = < 1 1 1 1 >;
		intel,block-status-enable = <540 26 1>;
		intel,block-enable = <516 26 1>;
		intel,block-divider-status = <676 25 3>;
		intel,block-disable = <528 26 1>;
		intel,block-divider = <596 0 3 596 8 3 596 16 3 596 24 3>;
		intel,block-divider-activate = <652 26 1>;
	};
	clk_gpu:clk_gpu {
		compatible = "intel,xgold-block-clock";
		#clock-cells = <0>;
		clock-output-names = "clk_gpu";
		clocks = <&MUX_GPU>;
		clock-names = "mux";
		intel,flags-divider_div_fix;
		intel,frequency-banks = < 4 >;
		intel,block-divider-default = < 1 1 1 1 >;
		intel,block-status-enable = <540 25 1>;
		intel,block-enable = <516 25 1>;
		intel,block-divider-status = <676 28 3>;
		intel,block-disable = <528 25 1>;
		intel,block-divider = <600 0 3 600 8 3 600 16 3 600 24 3>;
		intel,block-divider-activate = <652 25 1>;
	};
	clk_nandctrl:clk_nandctrl {
		compatible = "intel,xgold-block-clock";
		#clock-cells = <0>;
		clock-output-names = "clk_nandctrl";
		clocks = <&MUX_NANDCTRL>;
		clock-names = "mux";
		intel,block-status-enable = <544 19 1>;
		intel,block-enable = <520 19 1>;
		intel,block-disable = <532 19 1>;
	};
	clk_usim:clk_usim {
		compatible = "intel,xgold-block-clock";
		#clock-cells = <0>;
		clock-output-names = "clk_usim";
		clocks = <&MUX_USIM>;
		clock-names = "mux";
		intel,block-status-enable = <544 8 1>;
		intel,block-enable = <520 8 1>;
		intel,block-disable = <532 8 1>;
		intel,block-divider = <1008 0 8>;
	};
	clk_usim2:clk_usim2 {
		compatible = "intel,xgold-block-clock";
		#clock-cells = <0>;
		clock-output-names = "clk_usim2";
		clocks = <&MUX_USIM>;
		clock-names = "mux";
		intel,block-status-enable = <544 9 1>;
		intel,block-enable = <520 9 1>;
		intel,block-disable = <532 9 1>;
		intel,block-divider = <1008 8 8>;
	};
	clk_guciph:clk_guciph {
		compatible = "intel,xgold-block-clock";
		#clock-cells = <0>;
		clock-output-names = "clk_guciph";
		clocks = <&MUX_VSCALE>;
		clock-names = "mux";
		intel,flags-divider_div_fix;
		intel,frequency-banks = < 3 >;
		intel,block-divider-default = < 1 1 1 >;
		intel,block-status-enable = <544 7 1>;
		intel,block-enable = <520 7 1>;
		intel,block-divider-status = <664 12 3>;
		intel,block-disable = <532 7 1>;
		intel,block-divider = <568 0 3 568 8 3 568 16 3>;
		intel,block-divider-activate = <656 7 1>;
	};
	clk_dsp_2g:clk_dsp_2g {
		compatible = "intel,xgold-block-clock";
		#clock-cells = <0>;
		clock-output-names = "clk_dsp_2g";
		clocks = <&MUX_DSP_2G>;
		clock-names = "mux";
		intel,block-divider-default = < 1 1 1 >;
		intel,block-status-enable = <548 6 1>;
		intel,block-enable = <524 6 1>;
		intel,block-disable = <536 6 1>;
		intel,block-divider = <696 0 8>;
	};
	clk_dsp_aud:clk_dsp_aud {
		compatible = "intel,xgold-block-clock";
		#clock-cells = <0>;
		clock-output-names = "clk_dsp_aud";
		clocks = <&MUX_DSP_AUD>;
		clock-names = "mux";
		intel,block-divider-default = < 1 1 1 >;
		intel,block-status-enable = <548 4 1>;
		intel,block-enable = <524 4 1>;
		intel,block-disable = <536 4 1>;
		intel,block-divider = <704 0 8>;
	};
	int_dsp_aud_r:int_dsp_aud_r {
		compatible = "intel,xgold-block-clock";
		#clock-cells = <0>;
		clock-output-names = "int_dsp_aud_r";
		clocks = <&MUX_26M>;
		clock-names = "mux";
		intel,block-status-enable = <548 8 1>;
		intel,block-enable = <524 8 1>;
		intel,block-disable = <536 8 1>;
	};
	clk_ms_i2s1:clk_ms_i2s1 {
		compatible = "intel,xgold-block-clock";
		#clock-cells = <0>;
		clock-output-names = "clk_ms_i2s1";
		clocks = <&MUX_FIX1>;
		clock-names = "mux";
		intel,flags-divider_div_fix;
		intel,frequency-banks = < 3 >;
		intel,block-divider-default = < 1 1 1 >;
		intel,block-status-enable = <544 21 1>;
		intel,block-enable = <520 21 1>;
		intel,block-divider-status = <680 0 3>;
		intel,block-disable = <532 21 1>;
		intel,block-divider = <628 0 3 628 8 3 628 16 3>;
		intel,block-divider-activate = <656 21 1>;
	};
	clk_dig_mic:clk_dig_mic {
		compatible = "intel,xgold-block-clock";
		#clock-cells = <0>;
		clock-output-names = "clk_dig_mic";
		clocks = <&MUX_DIG_MIC>;
		clock-names = "mux";
		intel,block-divider-default = < 1 1 1 >;
		intel,block-status-enable = <544 20 1>;
		intel,block-enable = <520 20 1>;
		intel,block-disable = <532 20 1>;
		intel,block-divider = <1012 0 8>;
	};
	clk_cap0:clk_cap0 {
		compatible = "intel,xgold-block-clock";
		#clock-cells = <0>;
		clock-output-names = "clk_cap0";
		clocks = <&MUX_26M>;
		clock-names = "mux";
		intel,block-status-enable = <544 10 1>;
		intel,block-enable = <520 10 1>;
		intel,block-disable = <532 10 1>;
	};
	clk_cap1:clk_cap1 {
		compatible = "intel,xgold-block-clock";
		#clock-cells = <0>;
		clock-output-names = "clk_cap1";
		clocks = <&MUX_26M>;
		clock-names = "mux";
		intel,block-status-enable = <544 11 1>;
		intel,block-enable = <520 11 1>;
		intel,block-disable = <532 11 1>;
	};
	clk_gptu0:clk_gptu0 {
		compatible = "intel,xgold-block-clock";
		#clock-cells = <0>;
		clock-output-names = "clk_gptu0";
		clocks = <&MUX_26M>;
		clock-names = "mux";
		intel,block-status-enable = <544 13 1>;
		intel,block-enable = <520 13 1>;
		intel,block-disable = <532 13 1>;
	};
	clk_gptu1:clk_gptu1 {
		compatible = "intel,xgold-block-clock";
		#clock-cells = <0>;
		clock-output-names = "clk_gptu1";
		clocks = <&MUX_26M>;
		clock-names = "mux";
		intel,block-status-enable = <544 14 1>;
		intel,block-enable = <520 14 1>;
		intel,block-disable = <532 14 1>;
	};
	clk_dap_hclk:clk_dap_hclk {
		compatible = "intel,xgold-block-clock";
		#clock-cells = <0>;
		clock-output-names = "clk_dap_hclk";
		clocks = <&MUX_FIX1>;
		clock-names = "mux";
		intel,flags-ignore-unused;
		intel,flags-divider_div_fix;
		intel,frequency-banks = < 3 >;
		intel,block-divider-default = < 1 1 1 >;
		intel,block-status-enable = <544 5 1>;
		intel,block-enable = <520 5 1>;
		intel,block-divider-status = <680 6 3>;
		intel,block-disable = <532 5 1>;
		intel,block-divider = <636 0 3 636 8 3 636 16 3>;
		intel,block-divider-activate = <656 5 1>;
	};
	clk_mtm1:clk_mtm1 {
		compatible = "intel,xgold-block-clock";
		#clock-cells = <0>;
		clock-output-names = "clk_mtm1";
		clocks = <&MUX_TRACEOUT>;
		clock-names = "mux";
		intel,flags-divider_table1;
		intel,frequency-banks = < 3 >;
		intel,block-divider-default = < 1 1 1 >;
		intel,block-status-enable = <548 18 1>;
		intel,block-enable = <524 18 1>;
		intel,block-divider-status = <680 16 3>;
		intel,block-disable = <536 18 1>;
		intel,block-divider = <644 0 3 644 8 3 644 16 3>;
		intel,block-divider-activate = <660 17 1>;
	};
	clk_idi:clk_idi {
		compatible = "intel,xgold-block-clock";
		#clock-cells = <0>;
		clock-output-names = "clk_idi";
		clocks = <&MUX_IDI>;
		clock-names = "mux";
		intel,flags-ignore-unused;
		intel,flags-divider_div_fix;
		intel,frequency-banks = < 3 >;
		intel,block-divider-default = < 1 1 1 >;
		intel,block-status-enable = <548 30 1>;
		intel,block-enable = <524 30 1>;
		intel,block-divider-status = <680 25 3>;
		intel,block-disable = <536 30 1>;
		intel,block-divider = <948 0 3 948 8 3 948 16 3>;
		intel,block-divider-activate = <660 30 1>;
	};
	clk_idi_per:clk_idi_per {
		compatible = "intel,xgold-block-clock";
		#clock-cells = <0>;
		clock-output-names = "clk_idi_per";
		clocks = <&MUX_NOC>;
		clock-names = "mux";
		intel,flags-ignore-unused;
		intel,flags-divider_div_fix;
		intel,frequency-banks = < 4 >;
		intel,block-divider-default = < 1 2 4 4 >;
		intel,block-divider-default-div-fix = < 8 >;
		intel,block-status-enable = <548 31 1>;
		intel,block-enable = <524 31 1>;
		intel,block-divider-status = <680 28 3>;
		intel,block-disable = <536 31 1>;
		intel,block-divider = <952 0 3 952 8 3 952 16 3 952 24 3>;
		intel,block-divider-activate = <660 31 1>;
	};
	clk_mc2:clk_mc2 {
		compatible = "intel,xgold-block-clock";
		#clock-cells = <0>;
		clock-output-names = "clk_mc2";
		clocks = <&MUX_MC2>;
		clock-names = "mux";
		intel,block-status-enable = <544 3 1>;
		intel,block-enable = <520 3 1>;
		intel,block-disable = <532 3 1>;
	};
	clk_mc3:clk_mc3 {
		compatible = "intel,xgold-block-clock";
		#clock-cells = <0>;
		clock-output-names = "clk_mc3";
		clocks = <&MUX_26M>;
		clock-names = "mux";
		intel,block-status-enable = <544 4 1>;
		intel,block-enable = <520 4 1>;
		intel,block-disable = <532 4 1>;
	};
	clk_mc_ctrl:clk_mc_ctrl {
		compatible = "intel,xgold-block-clock";
		#clock-cells = <0>;
		clock-output-names = "clk_mc_ctrl";
		clocks = <&MUX_26M>;
		clock-names = "mux";
		intel,block-status-enable = <544 2 1>;
		intel,block-enable = <520 2 1>;
		intel,block-disable = <532 2 1>;
	};
	clk_czclk:clk_czclk {
		compatible = "intel,xgold-block-clock";
		#clock-cells = <0>;
		clock-output-names = "clk_czclk";
		clocks = <&MUX_CPU>;
		clock-names = "mux";
		intel,flags-divider_table1;
		intel,frequency-banks = < 4 >;
		intel,block-divider-default-div-fix = < 4 >;
		intel,block-divider-status = <676 16 3>;
		intel,block-divider = <612 0 3 612 8 3 612 16 3 612 24 3>;
		intel,block-divider-activate = <652 19 1>;
	};
};
